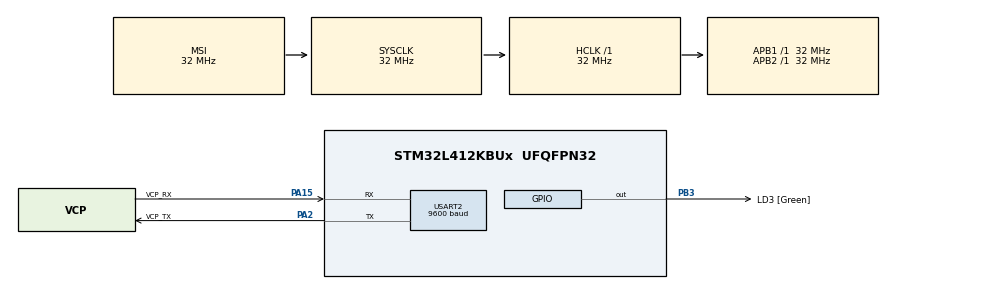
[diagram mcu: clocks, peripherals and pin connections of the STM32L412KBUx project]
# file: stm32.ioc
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Mcu.Family=STM32L4
Mcu.Name=STM32L412KBUx
Mcu.Package=UFQFPN32
NVIC.PriorityGroup=NVIC_PRIORITYGROUP_4
NVIC.RTC_Alarm_IRQn=true\:0\:0\:false\:false\:true\:true\:true
NVIC.USART2_IRQn=true\:0\:0\:false\:false\:true\:true\:true
PA0-CK_IN.Mode=HSE-External-Clock-Source-for-LittleOrca
PA0-CK_IN.Signal=RCC_CK_IN
PA13\ (JTMS/SWDIO).GPIO_Label=SWDIO
PA13\ (JTMS/SWDIO).Mode=Serial_Wire
PA13\ (JTMS/SWDIO).Signal=SYS_JTMS-SWDIO
PA14\ (JTCK/SWCLK).GPIO_Label=SWCLK
PA14\ (JTCK/SWCLK).Mode=Serial_Wire
PA14\ (JTCK/SWCLK).Signal=SYS_JTCK-SWCLK
PA15\ (JTDI).GPIO_Label=VCP_RX
PA15\ (JTDI).Mode=Asynchronous
PA15\ (JTDI).Signal=USART2_RX
PA2.GPIO_Label=VCP_TX
PA2.Mode=Asynchronous
PA2.Signal=USART2_TX
PB3\ (JTDO/TRACESWO).GPIO_Label=LD3 [Green]
PB3\ (JTDO/TRACESWO).Signal=GPIO_Output
PC14-OSC32_IN\ (PC14).Mode=LSE-External-Oscillator
PC14-OSC32_IN\ (PC14).Signal=RCC_OSC32_IN
PC15-OSC32_OUT\ (PC15).Mode=LSE-External-Oscillator
PC15-OSC32_OUT\ (PC15).Signal=RCC_OSC32_OUT
ProjectManager.HeapSize=0x200
ProjectManager.StackSize=0x400
ProjectManager.TargetToolchain=Makefile
RCC.ADCFreq_Value=32000000
RCC.AHBFreq_Value=32000000
RCC.APB1Freq_Value=32000000
RCC.APB1TimFreq_Value=32000000
RCC.APB2Freq_Value=32000000
RCC.APB2TimFreq_Value=32000000
RCC.CortexFreq_Value=32000000
RCC.FLatency=FLASH_LATENCY_1
RCC.HCLKFreq_Value=32000000
RCC.HSE_VALUE=8000000
RCC.HSI48_VALUE=48000000
RCC.HSICalibrationValue=16
RCC.HSI_VALUE=16000000
RCC.LSE_Drive_Capability=RCC_LSEDRIVE_LOW
RCC.MSIClockRange=RCC_MSIRANGE_10
RCC.MSI_VALUE=32000000
RCC.SYSCLKFreq_VALUE=32000000
RCC.USBFreq_Value=32000000
RCC.VCOOutputFreq_Value=256000000
RTC.Alarm=RTC_ALARM_A
RTC.AlarmMaskDateWeekDay=RTC_ALARMMASK_DATEWEEKDAY
RTC.AlarmMaskHours=RTC_ALARMMASK_HOURS
RTC.AlarmMaskMinutes=RTC_ALARMMASK_MINUTES
RTC.Seconds_A=30
USART2.BaudRate=9600
USART2.VirtualMode-Asynchronous=VM_ASYNC
VP_RTC_VS_RTC_Activate.Mode=RTC_Enabled
VP_RTC_VS_RTC_Alarm_A_Intern.Mode=Alarm A
VP_RTC_VS_RTC_Calendar.Mode=RTC_Calendar
board=NUCLEO-L412KB

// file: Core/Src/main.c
/* USER CODE BEGIN Header */
/**
  ******************************************************************************
  * @file           : main.c
  * @brief          : Main program body
  ******************************************************************************
  * @attention
  *
  * Copyright (c) 2022 STMicroelectronics.
  * All rights reserved.
  *
  * This software is licensed under terms that can be found in the LICENSE file
  * in the root directory of this software component.
  * If no LICENSE file comes with this software, it is provided AS-IS.
  *
  ******************************************************************************
  */
/* USER CODE END Header */
#include "main.h"

/* USER CODE BEGIN Includes */

#include "retarget/retarget.c"

/* USER CODE END Includes */

/* USER CODE BEGIN PD */
#define BUFFER_LENGTH RING_BUFFER_LENGTH

/* USER CODE END PD */

RTC_HandleTypeDef hrtc;

UART_HandleTypeDef huart2;

/* USER CODE BEGIN PV */
RingBuffer ring;
uint8_t alarm_flag = 0;

/* USER CODE END PV */

void SystemClock_Config(void);
static void MX_GPIO_Init(void);
static void MX_USART2_UART_Init(void);
static void MX_RTC_Init(void);

/* USER CODE BEGIN 0 */

void HAL_RTC_AlarmAEventCallback(RTC_HandleTypeDef *hrtc) {
  alarm_flag = 1;
}

/* USER CODE END 0 */

int main(void)
{
  /* USER CODE BEGIN 1 */
  uint8_t ch;
  RingBuffer_Init(&ring); // init ringbuffer
  uint8_t buffer[BUFFER_LENGTH];
  uint8_t *buff = buffer;
  /* USER CODE END 1 */

  /* MCU Configuration--------------------------------------------------------*/

  /* Reset of all peripherals, Initializes the Flash interface and the Systick. */
  HAL_Init();

  /* Configure the system clock */
  SystemClock_Config();

  /* Initialize all configured peripherals */
  MX_GPIO_Init();
  MX_USART2_UART_Init();
  MX_RTC_Init();
  /* USER CODE BEGIN 2 */
  HAL_UART_MspInit(&huart2); // enable NVIC interrupts for USART2
  RetargetInit(&huart2); // redirect IO to the screen
  printf("\r\nSystem Up and Running\n\r");
  prompt();
  /* USER CODE END 2 */

  /* Infinite loop */
  /* USER CODE BEGIN WHILE */
  while (1)
  {
    if(RingBuffer_GetDataLength(&ring) != 0){ // buffer has data
      // read from buffer
      RingBuffer_Read(&ring, &ch, 1);
      if (ch == '\r') {
        printf("\n\r");
        (*buff) = '\0';
        // printf("%s\n\r",buffer);
        execute_command(buffer);
        buff = buffer;
        prompt();
      } else {
        putchar(ch); // print input character to screen
        *(buff) = ch;
        buff++;
      }
    }
    if (alarm_flag) {
      alarm_flag = 0;
      lon();
      HAL_Delay(100);
      lof();
    }
    /* USER CODE END WHILE */

  }
}

void SystemClock_Config(void)
{
  RCC_OscInitTypeDef RCC_OscInitStruct = {0};
  RCC_ClkInitTypeDef RCC_ClkInitStruct = {0};

  /** Configure the main internal regulator output voltage
  */
  if (HAL_PWREx_ControlVoltageScaling(PWR_REGULATOR_VOLTAGE_SCALE1) != HAL_OK)
  {
    Error_Handler();
  }
  /** Configure LSE Drive Capability
  */
  HAL_PWR_EnableBkUpAccess();
  __HAL_RCC_LSEDRIVE_CONFIG(RCC_LSEDRIVE_LOW);
  /** Initializes the RCC Oscillators according to the specified parameters
  * in the RCC_OscInitTypeDef structure.
  */
  RCC_OscInitStruct.OscillatorType = RCC_OSCILLATORTYPE_LSI|RCC_OSCILLATORTYPE_LSE
                              |RCC_OSCILLATORTYPE_MSI;
  RCC_OscInitStruct.LSEState = RCC_LSE_ON;
  RCC_OscInitStruct.LSIState = RCC_LSI_ON;
  RCC_OscInitStruct.MSIState = RCC_MSI_ON;
  RCC_OscInitStruct.MSICalibrationValue = 0;
  RCC_OscInitStruct.MSIClockRange = RCC_MSIRANGE_10;
  RCC_OscInitStruct.PLL.PLLState = RCC_PLL_NONE;
  if (HAL_RCC_OscConfig(&RCC_OscInitStruct) != HAL_OK)
  {
    Error_Handler();
  }
  /** Initializes the CPU, AHB and APB buses clocks
  */
  RCC_ClkInitStruct.ClockType = RCC_CLOCKTYPE_HCLK|RCC_CLOCKTYPE_SYSCLK
                              |RCC_CLOCKTYPE_PCLK1|RCC_CLOCKTYPE_PCLK2;
  RCC_ClkInitStruct.SYSCLKSource = RCC_SYSCLKSOURCE_MSI;
  RCC_ClkInitStruct.AHBCLKDivider = RCC_SYSCLK_DIV1;
  RCC_ClkInitStruct.APB1CLKDivider = RCC_HCLK_DIV1;
  RCC_ClkInitStruct.APB2CLKDivider = RCC_HCLK_DIV1;

  if (HAL_RCC_ClockConfig(&RCC_ClkInitStruct, FLASH_LATENCY_1) != HAL_OK)
  {
    Error_Handler();
  }
  /** Enable MSI Auto calibration
  */
  HAL_RCCEx_EnableMSIPLLMode();
}

static void MX_RTC_Init(void)
{

  RTC_TimeTypeDef sTime = {0};
  RTC_DateTypeDef sDate = {0};
  RTC_AlarmTypeDef sAlarm = {0};

  /** Initialize RTC Only
  */
  hrtc.Instance = RTC;
  hrtc.Init.HourFormat = RTC_HOURFORMAT_24;
  hrtc.Init.AsynchPrediv = 127;
  hrtc.Init.SynchPrediv = 255;
  hrtc.Init.OutPut = RTC_OUTPUT_DISABLE;
  hrtc.Init.OutPutRemap = RTC_OUTPUT_REMAP_NONE;
  hrtc.Init.OutPutPolarity = RTC_OUTPUT_POLARITY_HIGH;
  hrtc.Init.OutPutType = RTC_OUTPUT_TYPE_OPENDRAIN;
  hrtc.Init.OutPutPullUp = RTC_OUTPUT_PULLUP_NONE;
  if (HAL_RTC_Init(&hrtc) != HAL_OK)
  {
    Error_Handler();
  }

  /** Initialize RTC and set the Time and Date
  */
  sTime.Hours = 0x0;
  sTime.Minutes = 0x0;
  sTime.Seconds = 0x0;
  sTime.DayLightSaving = RTC_DAYLIGHTSAVING_NONE;
  sTime.StoreOperation = RTC_STOREOPERATION_RESET;
  if (HAL_RTC_SetTime(&hrtc, &sTime, RTC_FORMAT_BCD) != HAL_OK)
  {
    Error_Handler();
  }
  sDate.WeekDay = RTC_WEEKDAY_MONDAY;
  sDate.Month = RTC_MONTH_JANUARY;
  sDate.Date = 0x1;
  sDate.Year = 0x0;

  if (HAL_RTC_SetDate(&hrtc, &sDate, RTC_FORMAT_BCD) != HAL_OK)
  {
    Error_Handler();
  }
  /** Enable the Alarm A
  */
  sAlarm.AlarmTime.Hours = 0x0;
  sAlarm.AlarmTime.Minutes = 0x0;
  sAlarm.AlarmTime.Seconds = 0x30;
  sAlarm.AlarmTime.SubSeconds = 0x0;
  sAlarm.AlarmTime.DayLightSaving = RTC_DAYLIGHTSAVING_NONE;
  sAlarm.AlarmTime.StoreOperation = RTC_STOREOPERATION_RESET;
  sAlarm.AlarmMask = RTC_ALARMMASK_DATEWEEKDAY|RTC_ALARMMASK_HOURS
                              |RTC_ALARMMASK_MINUTES;
  sAlarm.AlarmSubSecondMask = RTC_ALARMSUBSECONDMASK_ALL;
  sAlarm.AlarmDateWeekDaySel = RTC_ALARMDATEWEEKDAYSEL_DATE;
  sAlarm.AlarmDateWeekDay = 0x1;
  sAlarm.Alarm = RTC_ALARM_A;
  if (HAL_RTC_SetAlarm_IT(&hrtc, &sAlarm, RTC_FORMAT_BCD) != HAL_OK)
  {
    Error_Handler();
  }

}

static void MX_USART2_UART_Init(void)
{

  huart2.Instance = USART2;
  huart2.Init.BaudRate = 9600;
  huart2.Init.WordLength = UART_WORDLENGTH_8B;
  huart2.Init.StopBits = UART_STOPBITS_1;
  huart2.Init.Parity = UART_PARITY_NONE;
  huart2.Init.Mode = UART_MODE_TX_RX;
  huart2.Init.HwFlowCtl = UART_HWCONTROL_NONE;
  huart2.Init.OverSampling = UART_OVERSAMPLING_16;
  huart2.Init.OneBitSampling = UART_ONE_BIT_SAMPLE_DISABLE;
  huart2.AdvancedInit.AdvFeatureInit = UART_ADVFEATURE_NO_INIT;
  if (HAL_UART_Init(&huart2) != HAL_OK)
  {
    Error_Handler();
  }
  /* USER CODE BEGIN USART2_Init 2 */
  LL_USART_EnableIT_RXNE(USART2);
  /* USER CODE END USART2_Init 2 */

}

static void MX_GPIO_Init(void)
{
  GPIO_InitTypeDef GPIO_InitStruct = {0};

  /* GPIO Ports Clock Enable */
  __HAL_RCC_GPIOC_CLK_ENABLE();
  __HAL_RCC_GPIOA_CLK_ENABLE();
  __HAL_RCC_GPIOB_CLK_ENABLE();

  /*Configure GPIO pin Output Level */
  HAL_GPIO_WritePin(LD3_GPIO_Port, LD3_Pin, GPIO_PIN_RESET);

  /*Configure GPIO pin : LD3_Pin */
  GPIO_InitStruct.Pin = LD3_Pin;
  GPIO_InitStruct.Mode = GPIO_MODE_OUTPUT_PP;
  GPIO_InitStruct.Pull = GPIO_NOPULL;
  GPIO_InitStruct.Speed = GPIO_SPEED_FREQ_LOW;
  HAL_GPIO_Init(LD3_GPIO_Port, &GPIO_InitStruct);

}

void Error_Handler(void)
{
  __disable_irq();
  while (1)
  {
  }
}

#ifdef  USE_FULL_ASSERT
/**
  * @brief  Reports the name of the source file and the source line number
  *         where the assert_param error has occurred.
  * @param  file: pointer to the source file name
  * @param  line: assert_param error line source number
  * @retval None
  */
void assert_failed(uint8_t *file, uint32_t line)
{
  /* USER CODE BEGIN 6 */
  /* User can add his own implementation to report the file name and line number,
   *  eg: printf("Wrong parameters value: file %s on line %d\r\n", file, line) */
  /* USER CODE END 6 */
}
#endif /* USE_FULL_ASSERT */
